# HC32F467 register map
File version: 1.0
CPU: CM4 r0p1, little endian, MPU, FPU, 4 interrupt priority bits
Registers are 32-bit, read-write, reset 0x0 unless marked. A register's access mark holds for its fields unless they carry their own. Offsets are from the block's base; [hi:lo] are bit positions; {n}, {i} and the like mark numbered series.

## ICG
Base 0x00000400
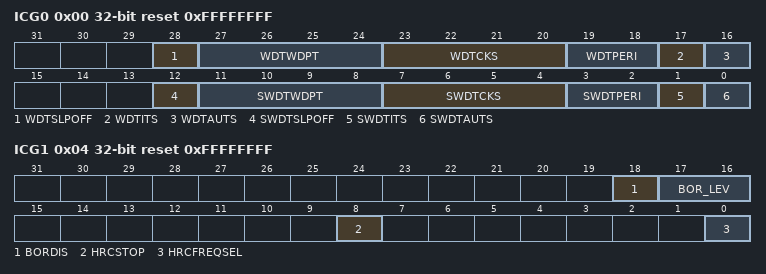
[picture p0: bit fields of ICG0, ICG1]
0x00 ICG0 ro reset 0xFFFFFFFF
  [28] WDTSLPOFF, [27:24] WDTWDPT, [23:20] WDTCKS, [19:18] WDTPERI, [17] WDTITS, [16] WDTAUTS, [12] SWDTSLPOFF, [11:8] SWDTWDPT, [7:4] SWDTCKS, [3:2] SWDTPERI, [1] SWDTITS, [0] SWDTAUTS
0x04 ICG1 ro reset 0xFFFFFFFF
  [18] BORDIS, [17:16] BOR_LEV, [8] HRCSTOP, [0] HRCFREQSEL
0x0C ICG3 ro reset 0xFFFFFFFF
  [15:0] DBUSPRT

## INTC
Base 0x40051000
0x00 NOCCR
  [13:12] NOCSEL
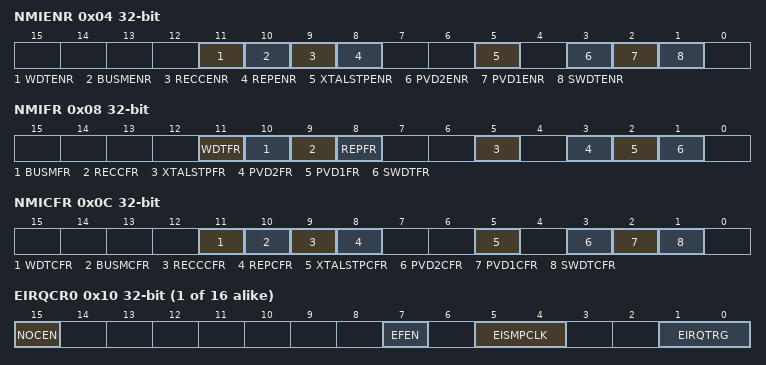
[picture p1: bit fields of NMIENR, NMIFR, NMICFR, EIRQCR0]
0x04 NMIENR
  [11] WDTENR, [10] BUSMENR, [9] RECCENR, [8] REPENR, [5] XTALSTPENR, [3] PVD2ENR, [2] PVD1ENR, [1] SWDTENR
0x08 NMIFR
  [11] WDTFR, [10] BUSMFR, [9] RECCFR, [8] REPFR, [5] XTALSTPFR, [3] PVD2FR, [2] PVD1FR, [1] SWDTFR
0x0C NMICFR
  [11] WDTCFR, [10] BUSMCFR, [9] RECCCFR, [8] REPCFR, [5] XTALSTPCFR, [3] PVD2CFR, [2] PVD1CFR, [1] SWDTCFR
{0x10+4i} EIRQCR{i} (i=0..15)
  [15] NOCEN, [7] EFEN, [5:4] EISMPCLK, [1:0] EIRQTRG
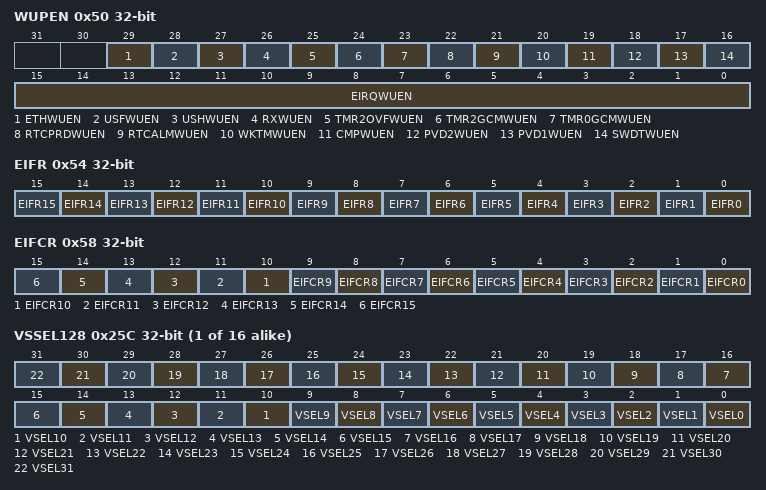
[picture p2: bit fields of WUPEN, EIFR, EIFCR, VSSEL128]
0x50 WUPEN
  [29] ETHWUEN, [28] USFWUEN, [27] USHWUEN, [26] RXWUEN, [25] TMR2OVFWUEN, [24] TMR2GCMWUEN, [23] TMR0GCMWUEN, [22] RTCPRDWUEN, [21] RTCALMWUEN, [20] WKTMWUEN, [19] CMPWUEN, [18] PVD2WUEN, [17] PVD1WUEN, [16] SWDTWUEN, [15:0] EIRQWUEN
0x54 EIFR
  [n] EIFR{n} (n=0..15)
0x58 EIFCR
  [n] EIFCR{n} (n=0..15)
{0x5C+4i} SEL{i} reset 0x1FF (i=0..127)
  [8:0] INTSEL
{0x5C+4i} VSSEL{i} (i=128..143)
  [n] VSEL{n} (n=0..31)
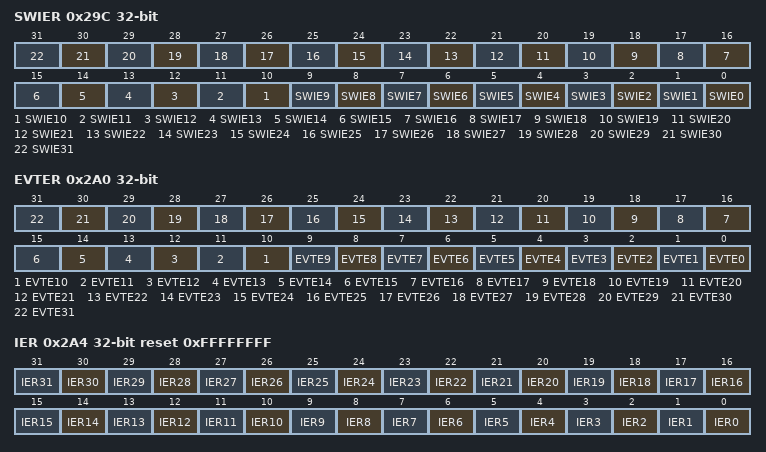
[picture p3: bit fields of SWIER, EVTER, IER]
0x29C SWIER
  [n] SWIE{n} (n=0..31)
0x2A0 EVTER
  [n] EVTE{n} (n=0..31)
0x2A4 IER reset 0xFFFFFFFF
  [n] IER{n} (n=0..31)

## KEYSCAN
Base 0x40050C00
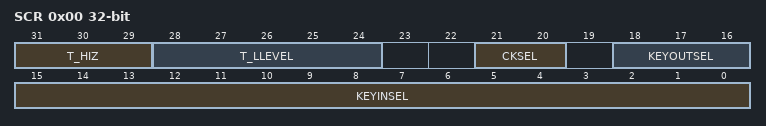
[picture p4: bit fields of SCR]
0x00 SCR
  [31:29] T_HIZ, [28:24] T_LLEVEL, [21:20] CKSEL, [18:16] KEYOUTSEL, [15:0] KEYINSEL
0x04 SER
  [0] SEN
0x08 SSR
  [2:0] INDEX

## MAU
Base 0x40055000
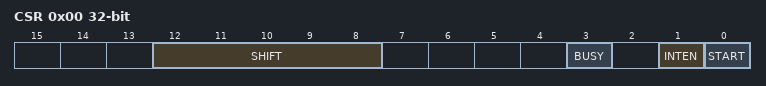
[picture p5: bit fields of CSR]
0x00 CSR
  [12:8] SHIFT, [3] BUSY ro, [1] INTEN, [0] START
0x04 DTR0
0x0C RTR0
  [16:0] SQRT_DOUT
0x10 DTR1
  [11:0] SIN_DIN
0x14 RTR1
  [15:0] SIN_DOUT

## MPU
Base 0x40050000; alternate view of ETH
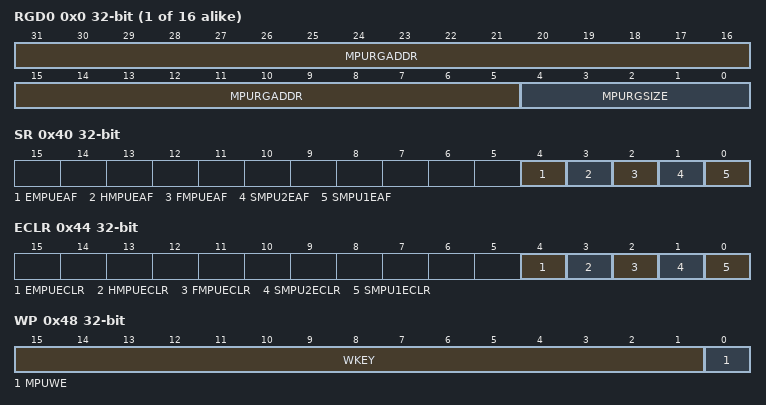
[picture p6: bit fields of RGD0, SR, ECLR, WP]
{0x0+4i} RGD{i} (i=0..15)
  [31:5] MPURGADDR, [4:0] MPURGSIZE
0x40 SR ro
  [4] EMPUEAF, [3] HMPUEAF, [2] FMPUEAF, [1] SMPU2EAF, [0] SMPU1EAF
0x44 ECLR wo
  [4] EMPUECLR, [3] HMPUECLR, [2] FMPUECLR, [1] SMPU2ECLR, [0] SMPU1ECLR
0x48 WP
  [15:1] WKEY, [0] MPUWE
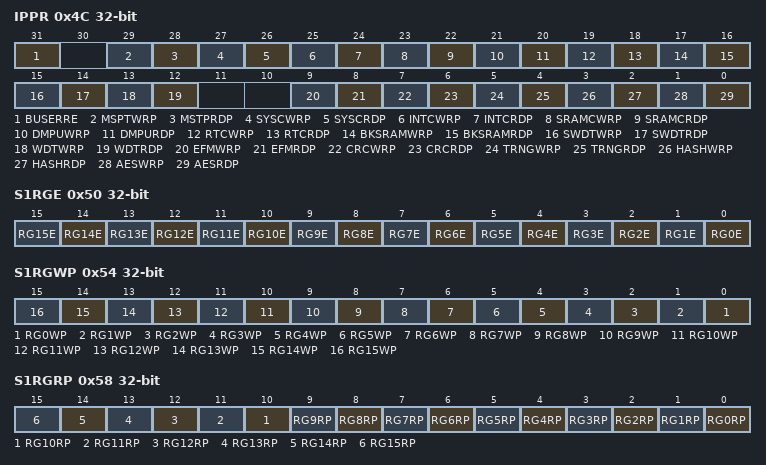
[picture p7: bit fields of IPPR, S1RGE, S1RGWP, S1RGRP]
0x4C IPPR
  [31] BUSERRE, [29] MSPTWRP, [28] MSTPRDP, [27] SYSCWRP, [26] SYSCRDP, [25] INTCWRP, [24] INTCRDP, [23] SRAMCWRP, [22] SRAMCRDP, [21] DMPUWRP, [20] DMPURDP, [19] RTCWRP, [18] RTCRDP, [17] BKSRAMWRP, [16] BKSRAMRDP, [15] SWDTWRP, [14] SWDTRDP, [13] WDTWRP, [12] WDTRDP, [9] EFMWRP, [8] EFMRDP, [7] CRCWRP, [6] CRCRDP, [5] TRNGWRP, [4] TRNGRDP, [3] HASHWRP, [2] HASHRDP, [1] AESWRP, [0] AESRDP
0x50 S1RGE
  [n] RG{n}E (n=0..15)
0x54 S1RGWP
  [n] RG{n}WP (n=0..15)
0x58 S1RGRP
  [n] RG{n}RP (n=0..15)
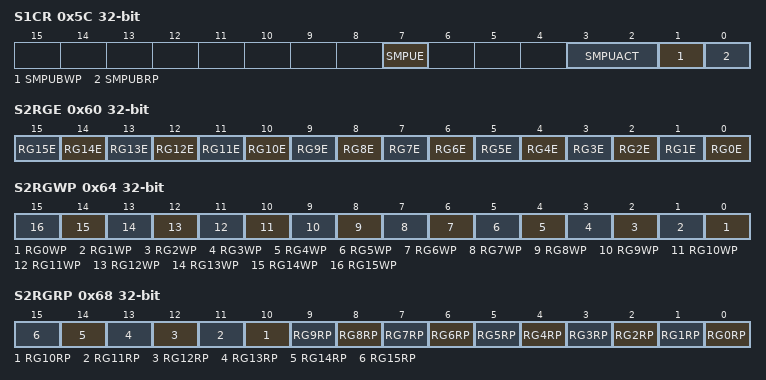
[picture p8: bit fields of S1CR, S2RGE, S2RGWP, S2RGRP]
0x5C S1CR
  [7] SMPUE, [3:2] SMPUACT, [1] SMPUBWP, [0] SMPUBRP
0x60 S2RGE
  [n] RG{n}E (n=0..15)
0x64 S2RGWP
  [n] RG{n}WP (n=0..15)
0x68 S2RGRP
  [n] RG{n}RP (n=0..15)
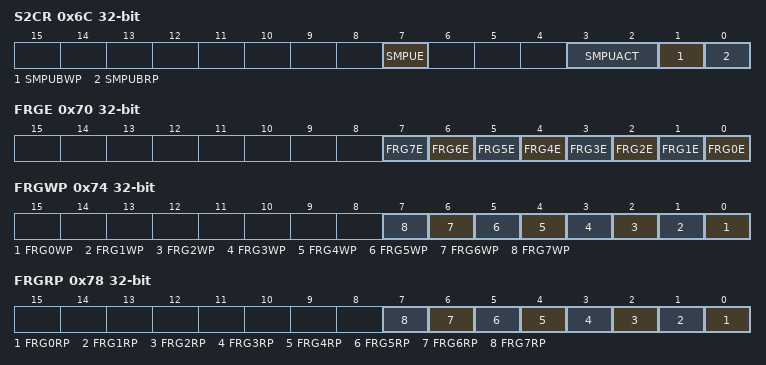
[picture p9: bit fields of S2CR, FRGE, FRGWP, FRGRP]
0x6C S2CR
  [7] SMPUE, [3:2] SMPUACT, [1] SMPUBWP, [0] SMPUBRP
0x70 FRGE
  [n] FRG{n}E (n=0..7)
0x74 FRGWP
  [n] FRG{n}WP (n=0..7)
0x78 FRGRP
  [n] FRG{n}RP (n=0..7)
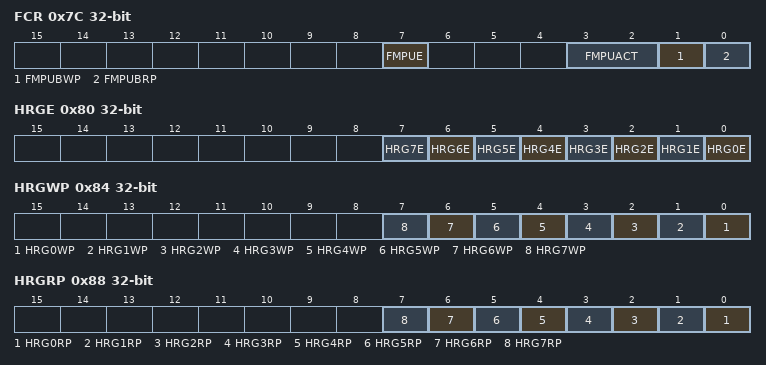
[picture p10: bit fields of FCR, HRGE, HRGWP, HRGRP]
0x7C FCR
  [7] FMPUE, [3:2] FMPUACT, [1] FMPUBWP, [0] FMPUBRP
0x80 HRGE
  [n] HRG{n}E (n=0..7)
0x84 HRGWP
  [n] HRG{n}WP (n=0..7)
0x88 HRGRP
  [n] HRG{n}RP (n=0..7)
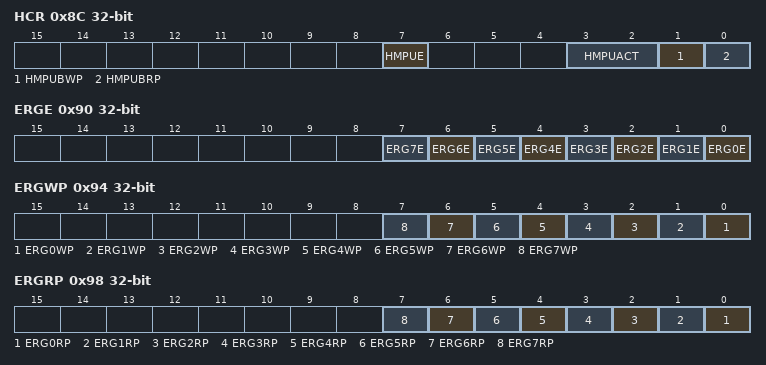
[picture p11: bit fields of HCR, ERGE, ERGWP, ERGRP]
0x8C HCR
  [7] HMPUE, [3:2] HMPUACT, [1] HMPUBWP, [0] HMPUBRP
0x90 ERGE
  [n] ERG{n}E (n=0..7)
0x94 ERGWP
  [n] ERG{n}WP (n=0..7)
0x98 ERGRP
  [n] ERG{n}RP (n=0..7)
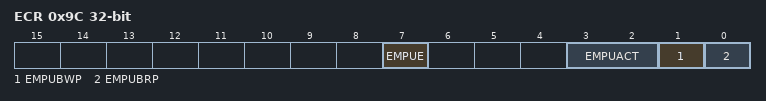
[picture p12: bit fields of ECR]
0x9C ECR
  [7] EMPUE, [3:2] EMPUACT, [1] EMPUBWP, [0] EMPUBRP

## NFC
Base 0x88100000
0x00 DATR_BASE
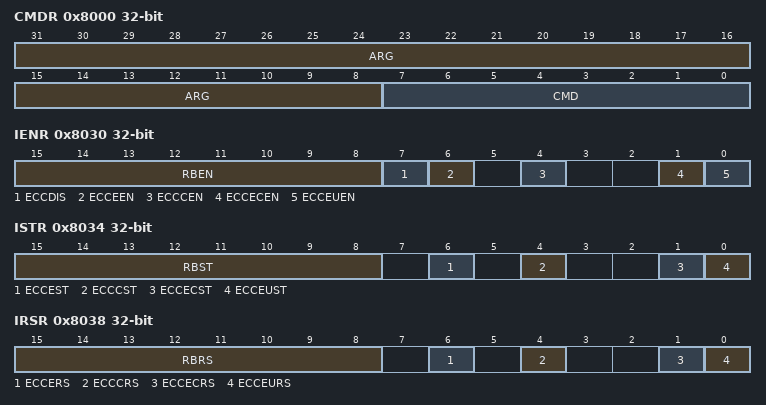
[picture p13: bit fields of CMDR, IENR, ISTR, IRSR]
0x8000 CMDR
  [31:8] ARG, [7:0] CMD
0x8004 IDXR0
0x8030 IENR
  [15:8] RBEN, [7] ECCDIS, [6] ECCEEN, [4] ECCCEN, [1] ECCECEN, [0] ECCEUEN
0x8034 ISTR
  [15:8] RBST, [6] ECCEST, [4] ECCCST, [1] ECCECST, [0] ECCEUST
0x8038 IRSR
  [15:8] RBRS, [6] ECCERS, [4] ECCCRS, [1] ECCECRS, [0] ECCEURS
0x8048 IDXR1
  [7:0] IDX1
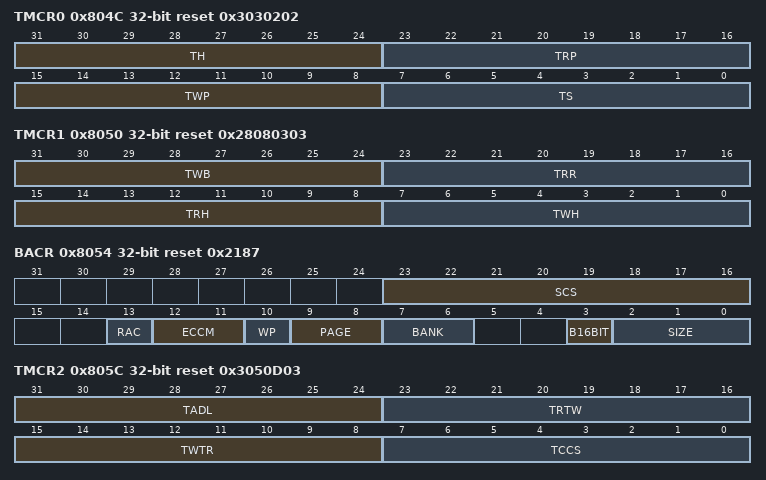
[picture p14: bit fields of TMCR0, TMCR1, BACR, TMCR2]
0x804C TMCR0 reset 0x3030202
  [31:24] TH, [23:16] TRP, [15:8] TWP, [7:0] TS
0x8050 TMCR1 reset 0x28080303
  [31:24] TWB, [23:16] TRR, [15:8] TRH, [7:0] TWH
0x8054 BACR reset 0x2187
  [23:16] SCS, [13] RAC, [12:11] ECCM, [10] WP, [9:8] PAGE, [7:6] BANK, [3] B16BIT, [2:0] SIZE
0x805C TMCR2 reset 0x3050D03
  [31:24] TADL, [23:16] TRTW, [15:8] TWTR, [7:0] TCCS
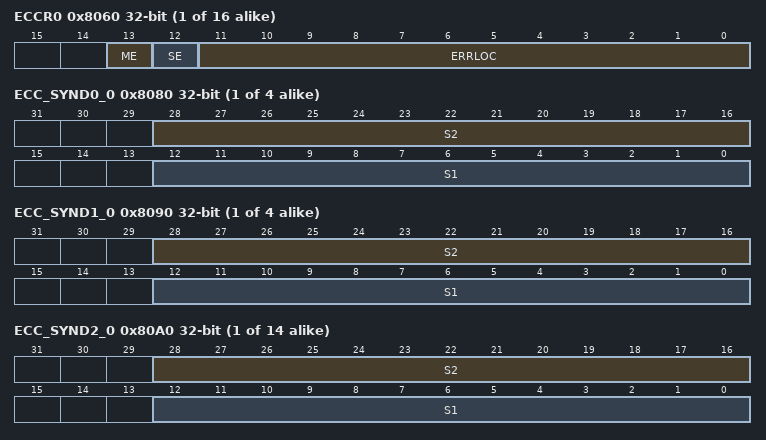
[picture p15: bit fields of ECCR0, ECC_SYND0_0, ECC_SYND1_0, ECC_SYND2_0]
{0x8060+4i} ECCR{i} ro (i=0..15)
  [13] ME, [12] SE, [11:0] ERRLOC
0x807C ECC_STAT ro (alternate view of ECCR7)
  [15:0] ERRSEC
{0x8080+4i} ECC_SYND0_{i} ro (alternate view of ECCR{i+8}) (i=0..3)
  [28:16] S{2i+2}, [12:0] S{2i+1}
{0x8090+4i} ECC_SYND1_{i} ro (alternate view of ECCR{i+12}) (i=0..3)
  [28:16] S{2i+2}, [12:0] S{2i+1}
{0x8080+0x10*i} ECC_SYND{i}_0 ro (i=2..15)
  [28:16] S2, [12:0] S1
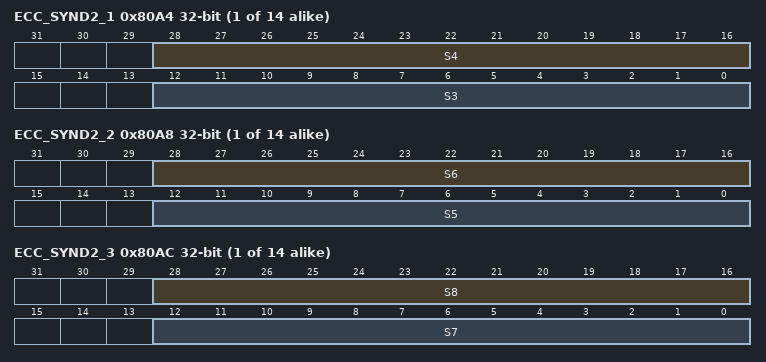
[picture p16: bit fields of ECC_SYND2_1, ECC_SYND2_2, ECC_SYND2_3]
{0x8084+0x10*i} ECC_SYND{i}_1 ro (i=2..15)
  [28:16] S4, [12:0] S3
{0x8088+0x10*i} ECC_SYND{i}_2 ro (i=2..15)
  [28:16] S6, [12:0] S5
{0x808C+0x10*i} ECC_SYND{i}_3 ro (i=2..15)
  [28:16] S8, [12:0] S7
